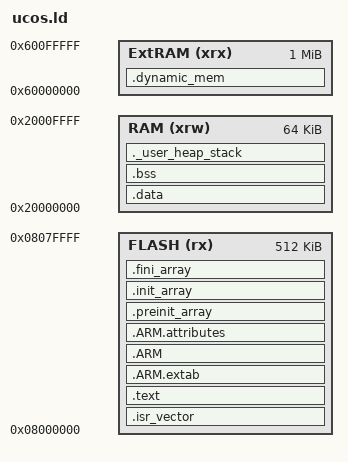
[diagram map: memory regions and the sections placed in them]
ENTRY(Reset_System)

/* highest address of the user mode's stack */
_estack = 0x20010000;    /* end of 64K RAM */

/* generate a link error if heap and stack don't fit into RAM */
_Min_Heap_Size = 0;      /* required amount of heap  */
_Min_Stack_Size = 0x200; /* required amount of stack */

/* Specify the memory areas */
MEMORY
{ /* STM32F103ZET6's FLASH */
  FLASH (rx)      : ORIGIN = 0x08000000, LENGTH = 512K
  /* STM32F103ZET6's SRAM */
  RAM (xrw)       : ORIGIN = 0x20000000, LENGTH = 64K
  /* outside SRAM with FSMC*/
  ExtRAM (xrx)  : ORIGIN = 0x60000000, LENGTH = 1024K
}

/* Define output sections */
SECTIONS
{
  /* The startup code goes first into FLASH */
  .isr_vector :
  {
    . = ALIGN(4);
    KEEP(*(.isr_vector)) /* Startup code */
    . = ALIGN(4);
  } >FLASH

  /* The program code and other data goes into FLASH */
  .text :
  {
    . = ALIGN(4);
    *(.text)           /* .text sections (code) */
    *(.text*)          /* .text* sections (code) */
    *(.rodata)         /* .rodata sections (constants, strings, etc.) */
    *(.rodata*)        /* .rodata* sections (constants, strings, etc.) */
    *(.glue_7)         /* glue arm to thumb code */
    *(.glue_7t)        /* glue thumb to arm code */

    KEEP (*(.init))
    KEEP (*(.fini))

    . = ALIGN(4);
    _etext = .;        /* define a global symbols at end of code */
  } >FLASH


   .ARM.extab   : { *(.ARM.extab* .gnu.linkonce.armextab.*) } >FLASH
    .ARM : {
    __exidx_start = .;
      *(.ARM.exidx*)
      __exidx_end = .;
    } >FLASH

  .ARM.attributes : { *(.ARM.attributes) } > FLASH

  .preinit_array     :
  {
    PROVIDE_HIDDEN (__preinit_array_start = .);
    KEEP (*(.preinit_array*))
    PROVIDE_HIDDEN (__preinit_array_end = .);
  } >FLASH
  .init_array :
  {
    PROVIDE_HIDDEN (__init_array_start = .);
    KEEP (*(SORT(.init_array.*)))
    KEEP (*(.init_array*))
    PROVIDE_HIDDEN (__init_array_end = .);
  } >FLASH
  .fini_array :
  {
    PROVIDE_HIDDEN (__fini_array_start = .);
    KEEP (*(.fini_array*))
    KEEP (*(SORT(.fini_array.*)))
    PROVIDE_HIDDEN (__fini_array_end = .);
  } >FLASH

  /* used by the startup to initialize data */
  _sidata = .;

  /* Initialized data sections goes into RAM, load LMA copy after code */
  .data : AT ( _sidata )
  {
    . = ALIGN(4);
    _sdata = .;        /* create a global symbol at data start */
    *(.data)           /* .data sections */
    *(.data*)          /* .data* sections */

    . = ALIGN(4);
    _edata = .;        /* define a global symbol at data end */
  } >RAM

  /* Uninitialized data section */
  . = ALIGN(4);
  .bss :
  {
    /* This is used by the startup in order to initialize the .bss secion */
    _sbss = .;         /* define a global symbol at bss start */
    __bss_start__ = _sbss;
    *(.bss)
    *(.bss*)
    *(COMMON)

    . = ALIGN(4);
    _ebss = .;         /* define a global symbol at bss end */
    __bss_end__ = _ebss;
  } >RAM

  PROVIDE ( end = _ebss );
  PROVIDE ( _end = _ebss );

  /* User_heap_stack section, used to check that there is enough RAM left */
  ._user_heap_stack :
  {
    . = ALIGN(4);
    . = . + _Min_Heap_Size;
    . = . + _Min_Stack_Size;
    . = ALIGN(4);
  } >RAM

  /* MEMORY_bank1 section, code must be located here explicitly            */
  .dynamic_mem :
  {
    . = ALIGN(4);
    *(.dynamic_mem)
    *(.dynamic_mem*)
    . = ALIGN(4);
  } > ExtRAM

  /* Remove information from the standard libraries */
  /DISCARD/ :
  {
    libc.a ( * )
    libm.a ( * )
    libgcc.a ( * )
  }
}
